VERSION ""

NS_ :

BS_:

BU_: XXX

BO_ 85 CID_QSLGZN: 8 XXX
 SG_ sig_kaaimy : 40|1@1+ (1,0) [0|1] "" XXX
 SG_ sig_qomzev : 56|8@1+ (1,0) [0|255] "" XXX

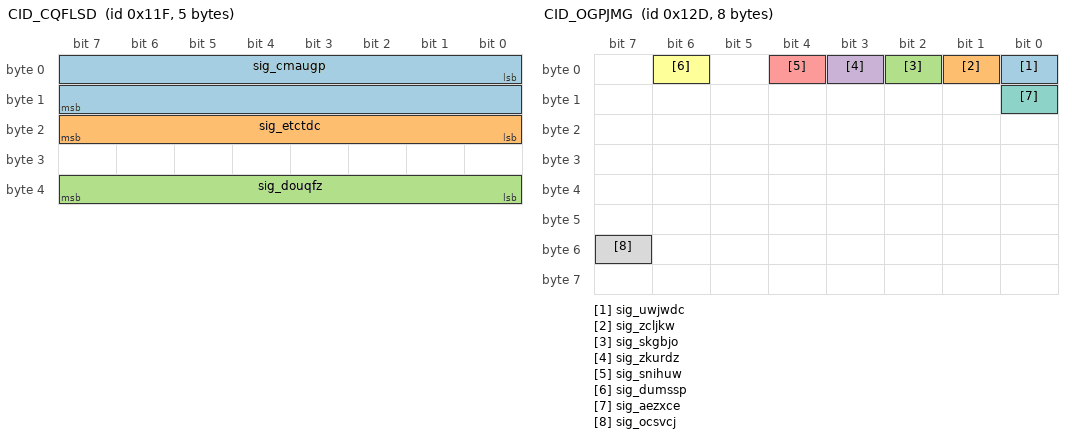
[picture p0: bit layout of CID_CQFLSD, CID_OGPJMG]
BO_ 287 CID_CQFLSD: 5 XXX
 SG_ sig_cmaugp : 0|16@1- (0.1,0) [-450|450] "" XXX
 SG_ sig_etctdc : 16|8@1+ (4,0) [0|1020] "" XXX
 SG_ sig_douqfz : 32|8@1+ (1,0) [0|255] "" XXX

BO_ 289 CID_GMYCTV: 8 XXX
 SG_ sig_hkwdos : 0|12@1+ (1,0) [0|255] "" XXX

BO_ 301 CID_OGPJMG: 8 XXX
 SG_ sig_uwjwdc : 0|1@0+ (1,0) [0|1] "" XXX
 SG_ sig_zcljkw : 1|1@0+ (1,0) [0|1] "" XXX
 SG_ sig_skgbjo : 2|1@0+ (1,0) [0|1] "" XXX
 SG_ sig_zkurdz : 3|1@0+ (1,0) [0|1] "" XXX
 SG_ sig_snihuw : 4|1@0+ (1,0) [0|1] "" XXX
 SG_ sig_dumssp : 6|1@0+ (1,0) [0|1] "" XXX
 SG_ sig_aezxce : 8|1@0+ (1,0) [0|1] "" XXX
 SG_ sig_ocsvcj : 55|1@0+ (1,0) [0|1] "" XXX

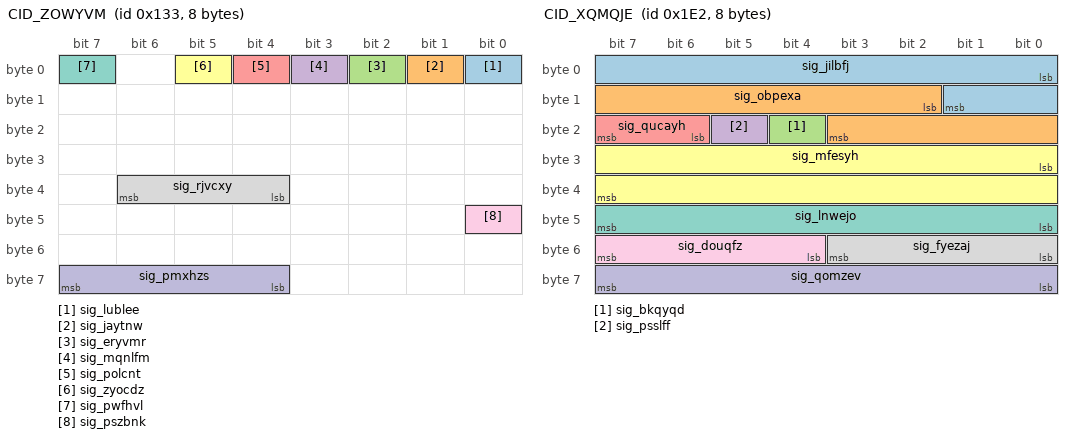
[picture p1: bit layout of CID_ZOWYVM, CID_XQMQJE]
BO_ 307 CID_ZOWYVM: 8 XXX
 SG_ sig_lublee : 0|1@0+ (1,0) [0|1] "" XXX
 SG_ sig_jaytnw : 1|1@1+ (1,0) [0|1] "" XXX
 SG_ sig_eryvmr : 2|1@1+ (1,0) [0|1] "" XXX
 SG_ sig_mqnlfm : 3|1@1+ (1,0) [0|1] "" XXX
 SG_ sig_polcnt : 4|1@0+ (1,0) [0|1] "" XXX
 SG_ sig_zyocdz : 5|1@0+ (1,0) [0|1] "" XXX
 SG_ sig_pwfhvl : 7|1@0+ (1,0) [0|1] "" XXX
 SG_ sig_rjvcxy : 36|3@1+ (1,0) [0|7] "" XXX
 SG_ sig_pszbnk : 40|1@0+ (1,0) [0|1] "" XXX
 SG_ sig_pmxhzs : 63|4@0+ (1,0) [0|15] "" XXX

BO_ 482 CID_XQMQJE: 8 XXX
 SG_ sig_jilbfj : 0|10@1- (0.01,0) [0|5] "" XXX
 SG_ sig_obpexa : 10|10@1- (0.01,0) [-5|0] "" XXX
 SG_ sig_bkqyqd : 20|1@0+ (1,0) [0|1] "" XXX
 SG_ sig_psslff : 21|1@0+ (1,0) [0|1] "" XXX
 SG_ sig_qucayh : 22|2@1+ (1,0) [0|1] "" XXX
 SG_ sig_mfesyh : 24|16@1- (0.1,0) [-780|779.9] "" XXX
 SG_ sig_lnwejo : 47|8@0+ (1,0) [0|255] "" XXX
 SG_ sig_fyezaj : 48|4@1+ (1,0) [0|15] "" XXX
 SG_ sig_douqfz : 52|4@1+ (1,0) [0|15] "" XXX
 SG_ sig_qomzev : 56|8@1+ (1,0) [0|255] "" XXX

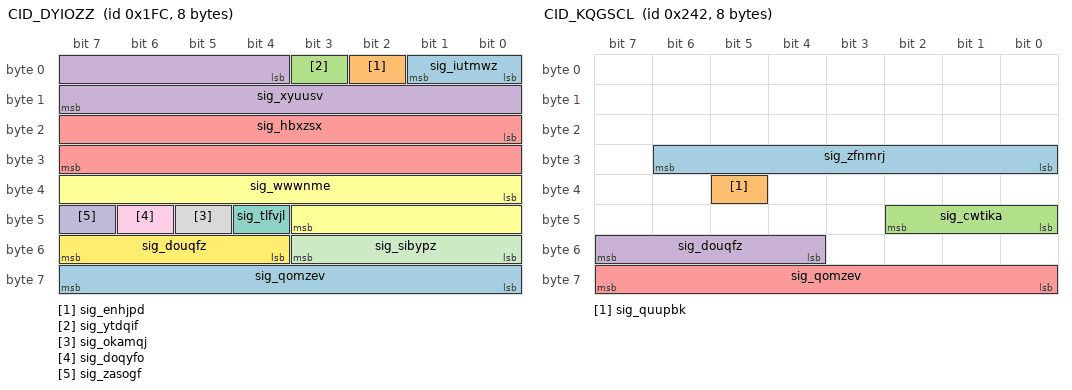
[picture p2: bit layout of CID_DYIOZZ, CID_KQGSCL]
BO_ 508 CID_DYIOZZ: 8 XXX
 SG_ sig_iutmwz : 0|2@1+ (1,0) [0|1] "" XXX
 SG_ sig_enhjpd : 2|1@1+ (1,0) [0|1] "" XXX
 SG_ sig_ytdqif : 3|1@0+ (1,0) [0|1] "" XXX
 SG_ sig_xyuusv : 4|12@1- (1,0) [-2048|2047] "" XXX
 SG_ sig_hbxzsx : 16|16@1- (0.1,0) [-780|779.9] "Deg" XXX
 SG_ sig_wwwnme : 32|12@1- (0.01,0) [0|63] "" XXX
 SG_ sig_tlfvjl : 44|1@0+ (1,0) [0|1] "" XXX
 SG_ sig_okamqj : 45|1@1+ (1,0) [0|255] "" XXX
 SG_ sig_doqyfo : 46|1@1+ (1,0) [0|1] "" XXX
 SG_ sig_zasogf : 47|1@0+ (1,0) [0|3] "" XXX
 SG_ sig_sibypz : 48|4@1+ (1,0) [0|15] "" XXX
 SG_ sig_douqfz : 52|4@1+ (1,0) [0|15] "" XXX
 SG_ sig_qomzev : 56|8@1+ (1,0) [0|255] "" XXX

BO_ 578 CID_KQGSCL: 8 XXX
 SG_ sig_zfnmrj : 30|7@0+ (1,0) [0|127] "" XXX
 SG_ sig_quupbk : 37|1@0+ (1,0) [0|1] "" XXX
 SG_ sig_cwtika : 40|3@1+ (1,0) [0|7] "" XXX
 SG_ sig_douqfz : 55|4@0+ (1,0) [0|15] "" XXX
 SG_ sig_qomzev : 56|8@1+ (1,0) [0|255] "" XXX

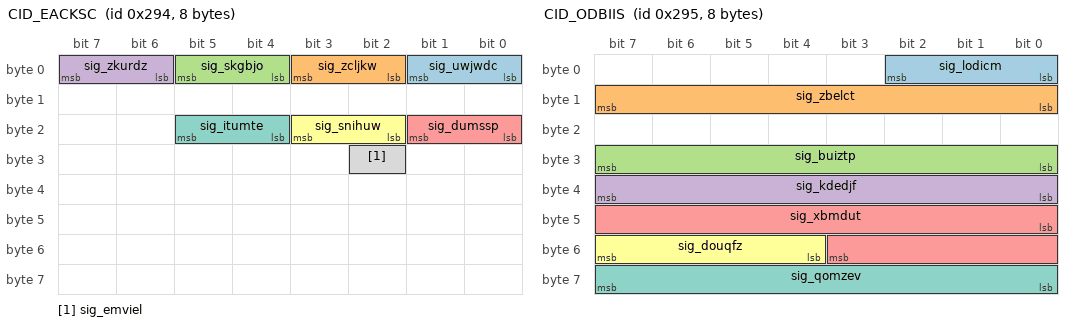
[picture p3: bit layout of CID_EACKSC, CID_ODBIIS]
BO_ 660 CID_EACKSC: 8 XXX
 SG_ sig_uwjwdc : 1|2@0+ (1,0) [0|3] "" XXX
 SG_ sig_zcljkw : 3|2@0+ (1,0) [0|3] "" XXX
 SG_ sig_skgbjo : 5|2@0+ (1,0) [0|3] "" XXX
 SG_ sig_zkurdz : 7|2@0+ (1,0) [0|3] "" XXX
 SG_ sig_dumssp : 17|2@0+ (1,0) [0|3] "" XXX
 SG_ sig_snihuw : 19|2@0+ (1,0) [0|3] "" XXX
 SG_ sig_itumte : 21|2@0+ (1,0) [0|3] "" XXX
 SG_ sig_emviel : 26|1@0+ (1,0) [0|1] "" XXX

BO_ 661 CID_ODBIIS: 8 XXX
 SG_ sig_lodicm : 2|3@0+ (1,0) [0|7] "" XXX
 SG_ sig_zbelct : 15|8@0+ (1,0) [0|255] "" XXX
 SG_ sig_buiztp : 31|8@0+ (1,0) [0|255] "" XXX
 SG_ sig_kdedjf : 32|8@1+ (1,0) [0|255] "" XXX
 SG_ sig_xbmdut : 40|12@1+ (1,0) [0|255] "" XXX
 SG_ sig_douqfz : 52|4@1+ (1,0) [0|15] "" XXX
 SG_ sig_qomzev : 63|8@0+ (1,0) [0|255] "" XXX

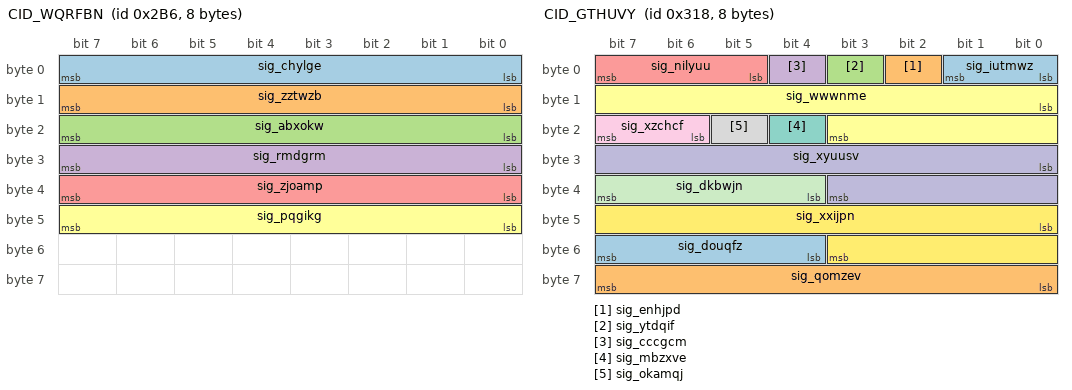
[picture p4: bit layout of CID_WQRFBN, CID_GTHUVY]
BO_ 694 CID_WQRFBN: 8 XXX
 SG_ sig_chylge : 7|8@0+ (1,0) [0|255] "" XXX
 SG_ sig_zztwzb : 15|8@0+ (1,0) [0|255] "" XXX
 SG_ sig_abxokw : 23|8@0+ (1,0) [0|255] "" XXX
 SG_ sig_rmdgrm : 31|8@0+ (1,0) [0|255] "" XXX
 SG_ sig_zjoamp : 39|8@0+ (1,0) [0|255] "" XXX
 SG_ sig_pqgikg : 47|8@0+ (1,0) [0|255] "" XXX

BO_ 790 CID_XFBVQJ: 8 XXX
 SG_ sig_ikzxrb : 3|4@0+ (1,0) [0|1] "" XXX
 SG_ sig_jbtudz : 4|2@1+ (1,0) [0|3] "" XXX
 SG_ sig_bneoxs : 6|2@1+ (1,0) [0|3] "" XXX
 SG_ sig_vgivbn : 8|2@1+ (1,0) [0|3] "" XXX
 SG_ sig_bjxtpp : 10|1@1+ (1,0) [0|1] "" XXX
 SG_ sig_oitzdg : 11|4@1+ (1,0) [0|1] "" XXX
 SG_ sig_bchklg : 15|1@0+ (1,0) [0|1] "" XXX
 SG_ sig_mfesyh : 16|11@1- (1,0) [-1024|1023] "" XXX
 SG_ sig_bkqyqd : 27|1@1+ (1,0) [0|1] "" XXX
 SG_ sig_psslff : 28|1@1+ (1,0) [0|3] "" XXX
 SG_ sig_rpmbgt : 29|1@0+ (1,0) [0|1] "" XXX
 SG_ sig_ahbkpp : 30|1@0+ (1,0) [0|1] "" XXX
 SG_ sig_ujplgt : 31|1@0+ (1,0) [0|1] "" XXX
 SG_ sig_lvrget : 32|2@1+ (1,0) [0|3] "" XXX
 SG_ sig_insdek : 34|2@1+ (1,0) [0|3] "" XXX
 SG_ sig_gfedbs : 36|4@1+ (1,0) [0|3] "" XXX
 SG_ sig_juyndg : 40|8@1+ (5,-5) [-5|1270] "" XXX
 SG_ sig_tcztfe : 49|2@0+ (1,0) [0|3] "" XXX
 SG_ sig_uvfhti : 51|2@0+ (1,0) [0|3] "" XXX
 SG_ sig_douqfz : 52|4@1+ (1,0) [0|15] "" XXX
 SG_ sig_qomzev : 56|8@1+ (1,0) [0|15] "" XXX

BO_ 792 CID_GTHUVY: 8 XXX
 SG_ sig_iutmwz : 0|2@1+ (1,0) [0|1] "" XXX
 SG_ sig_enhjpd : 2|1@1+ (1,0) [0|1] "" XXX
 SG_ sig_ytdqif : 3|1@1+ (1,0) [0|1] "" XXX
 SG_ sig_cccgcm : 4|1@1+ (1,0) [0|1] "" XXX
 SG_ sig_nilyuu : 5|3@1+ (1,0) [0|1] "" XXX
 SG_ sig_wwwnme : 8|12@1- (1,0) [-2048|2047] "" XXX
 SG_ sig_mbzxve : 20|1@1+ (1,0) [0|1] "" XXX
 SG_ sig_okamqj : 21|1@1+ (1,0) [0|1] "" XXX
 SG_ sig_xzchcf : 22|2@1+ (1,0) [0|15] "" XXX
 SG_ sig_xyuusv : 24|12@1- (1,0) [-2048|2047] "" XXX
 SG_ sig_dkbwjn : 36|4@1+ (1,0) [0|15] "" XXX
 SG_ sig_xxijpn : 40|12@1+ (1,0) [0|4095] "" XXX
 SG_ sig_douqfz : 52|4@1+ (1,0) [0|15] "" XXX
 SG_ sig_qomzev : 56|8@1+ (1,0) [0|255] "" XXX

BO_ 813 CID_NGPYLM: 8 XXX
 SG_ sig_xguccc : 0|9@1+ (0.5,0) [0|255.5] "" XXX
 SG_ sig_zjuxgf : 9|1@1+ (1,0) [0|1] "" XXX
 SG_ sig_ienwac : 10|3@1+ (1,0) [0|7] "" XXX
 SG_ sig_emctvm : 13|3@1+ (1,0) [0|7] "" XXX
 SG_ sig_gbkifq : 16|1@1+ (1,0) [0|1] "" XXX
 SG_ sig_mnkjgo : 17|1@1+ (1,0) [0|1] "" XXX
 SG_ sig_ytdqif : 18|1@1+ (1,0) [0|1] "" XXX
 SG_ sig_pnemyu : 19|3@1+ (1,0) [0|1] "" XXX
 SG_ sig_vvgvya : 22|1@0+ (1,0) [0|1] "" XXX
 SG_ sig_wpscbp : 23|1@0+ (1,0) [0|1] "" XXX
 SG_ sig_vgivbn : 24|1@1+ (1,0) [0|1] "" XXX
 SG_ sig_sllsbl : 25|7@1+ (1,0) [0|127] "" XXX
 SG_ sig_quqnip : 32|4@1+ (1,0) [0|15] "" XXX
 SG_ sig_dyvfen : 36|12@1+ (1,0) [0|4095] "" XXX
 SG_ sig_douqfz : 48|4@1+ (1,0) [0|15] "" XXX
 SG_ sig_sfdsag : 55|4@0+ (1,0) [0|15] "" XXX
 SG_ sig_qomzev : 56|8@1+ (1,0) [0|255] "" XXX

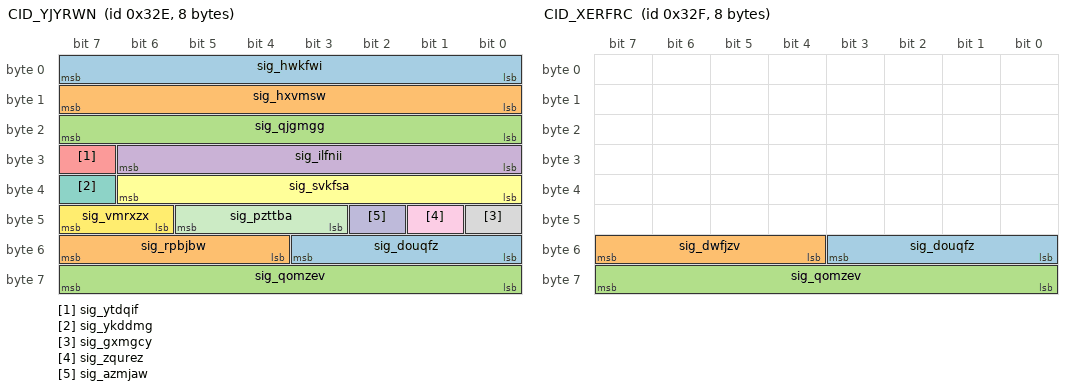
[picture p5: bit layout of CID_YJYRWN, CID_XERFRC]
BO_ 814 CID_YJYRWN: 8 XXX
 SG_ sig_hwkfwi : 0|8@1+ (0.05,-5) [-100|155] "" XXX
 SG_ sig_hxvmsw : 8|8@1+ (0.05,-5) [0|1.26] "" XXX
 SG_ sig_qjgmgg : 16|8@1+ (0.05,-5) [0|1.26] "" XXX
 SG_ sig_ilfnii : 24|7@1+ (0.2,0) [0|12.7] "" XXX
 SG_ sig_ytdqif : 31|1@0+ (1,0) [0|1] "" XXX
 SG_ sig_svkfsa : 32|7@1+ (0.2,-16) [0|12.7] "" XXX
 SG_ sig_ykddmg : 39|1@0+ (1,0) [0|1] "" XXX
 SG_ sig_gxmgcy : 40|1@0+ (1,0) [0|1] "" XXX
 SG_ sig_zqurez : 41|1@0+ (1,0) [0|1] "" XXX
 SG_ sig_azmjaw : 42|1@1+ (1,0) [0|3] "" XXX
 SG_ sig_pzttba : 45|3@0+ (1,0) [0|1] "" XXX
 SG_ sig_vmrxzx : 46|2@1+ (1,0) [0|3] "" XXX
 SG_ sig_douqfz : 48|4@1+ (1,0) [0|15] "" XXX
 SG_ sig_rpbjbw : 55|4@0+ (1,0) [0|15] "" XXX
 SG_ sig_qomzev : 56|8@1+ (1,0) [0|255] "" XXX

BO_ 815 CID_XERFRC: 8 XXX
 SG_ sig_douqfz : 48|4@1+ (1,0) [0|15] "" XXX
 SG_ sig_dwfjzv : 55|4@0+ (1,0) [0|15] "" XXX
 SG_ sig_qomzev : 56|8@1+ (1,0) [0|255] "" XXX

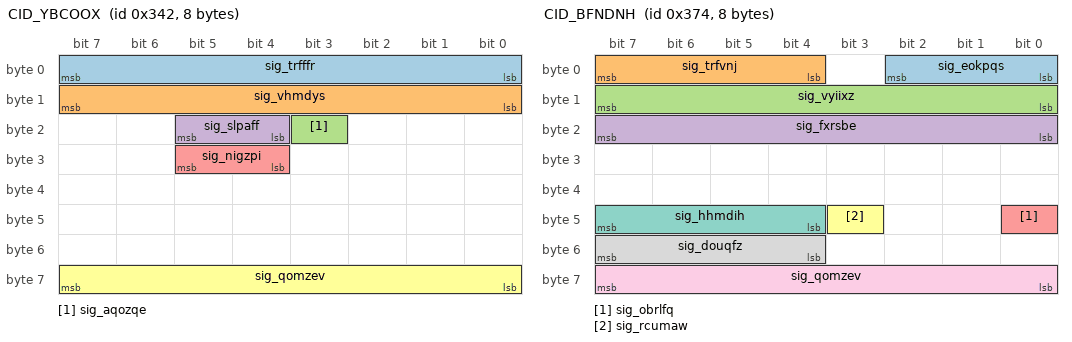
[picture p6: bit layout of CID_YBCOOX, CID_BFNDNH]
BO_ 834 CID_YBCOOX: 8 XXX
 SG_ sig_trfffr : 0|8@1+ (0.01,0) [0|2.55] "" XXX
 SG_ sig_vhmdys : 8|8@1+ (0.01,0) [0|2.55] "" XXX
 SG_ sig_aqozqe : 19|1@1+ (1,0) [0|1] "" XXX
 SG_ sig_slpaff : 20|2@1+ (1,0) [0|255] "" XXX
 SG_ sig_nigzpi : 28|2@1+ (1,0) [0|1] "" XXX
 SG_ sig_qomzev : 56|8@1+ (1,0) [0|255] "" XXX

 BO_ 884 CID_BFNDNH: 8 MRR
 SG_ sig_eokpqs : 2|3@0+ (1,0) [0|3] "" MRR
 SG_ sig_trfvnj : 7|4@0+ (1,0) [0|15] "" MRR
 SG_ sig_vyiixz : 15|8@0+ (0.1,-12) [0|255] "" MRR
 SG_ sig_fxrsbe : 23|8@0+ (1,-100) [0|255] "" MRR
 SG_ sig_obrlfq : 40|1@0+ (1,0) [0|3] "" MRR
 SG_ sig_rcumaw : 43|1@0+ (1,0) [0|1] "" XXX
 SG_ sig_hhmdih : 44|4@1+ (1,0) [0|15] "" XXX
 SG_ sig_douqfz : 52|4@1+ (1,0) [0|15] "" MRR
 SG_ sig_qomzev : 56|8@1+ (1,0) [0|255] "" MRR

BO_ 944 CID_ZJJZNE: 8 XXX
 SG_ sig_othvds : 1|2@0+ (1,0) [0|3] "" XXX
 SG_ sig_mmpery : 2|1@0+ (1,0) [0|1] "" XXX
 SG_ sig_cdkihw : 4|2@0+ (1,0) [0|3] "" XXX
 SG_ sig_rqtctv : 5|1@0+ (1,0) [0|1] "" XXX
 SG_ sig_vylajm : 6|1@0+ (1,0) [0|1] "" XXX
 SG_ sig_tpydsr : 7|1@0+ (1,0) [0|1] "" XXX
 SG_ sig_mnmkuo : 8|1@0+ (1,0) [0|1] "" XXX
 SG_ sig_hqlzon : 11|3@0+ (1,0) [0|7] "" XXX
 SG_ sig_ybkqsp : 12|1@0+ (1,0) [0|1] "" XXX
 SG_ sig_kmwymf : 14|2@0+ (1,0) [0|3] "" XXX
 SG_ sig_gsvszp : 15|1@0+ (1,0) [0|1] "" XXX
 SG_ sig_wxduqq : 16|1@0+ (1,0) [0|1] "" XXX
 SG_ sig_xzyhis : 18|2@0+ (1,0) [0|3] "" XXX
 SG_ sig_hgmxtb : 19|1@0+ (1,0) [0|1] "" XXX
 SG_ sig_gjctkz : 23|4@0+ (1,0) [0|15] "" XXX
 SG_ sig_jkflrx : 24|28@1+ (1,0) [0|268435455] "" XXX
 SG_ sig_douqfz : 52|4@1+ (1,0) [0|15] "" XXX
 SG_ sig_qomzev : 56|8@1+ (1,0) [0|255] "" XXX

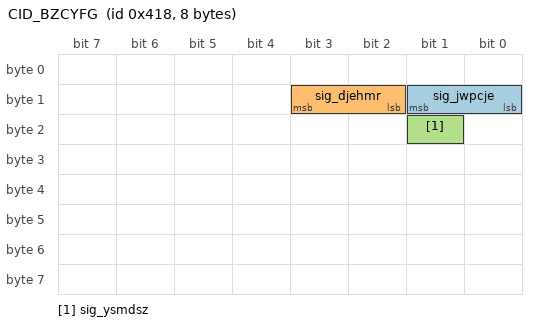
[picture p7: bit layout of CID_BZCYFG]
BO_ 1048 CID_BZCYFG: 8 XXX
 SG_ sig_jwpcje : 9|2@0+ (1,0) [0|1] "" XXX
 SG_ sig_djehmr : 11|2@0+ (1,0) [0|1] "" XXX
 SG_ sig_ysmdsz : 17|1@0+ (1,0) [0|1] "" XXX

VAL_ 578 sig_cwtika 4 "D" 2 "R" 3 "N" 1 "P";
VAL_ 790 sig_ikzxrb 11 "AutoFullBeamActive" 2 "AutoFullBeamInactive";
VAL_ 790 sig_jbtudz 0 "GRAY" 1 "GREEN" 2 "YELLOW" 3 "RED";
VAL_ 790 sig_bneoxs 3 "ALARM_AND_LKA" 2 "LKA" 1 "ALARM" 0 "DISABLE";
VAL_ 790 sig_insdek 0 "GRAY" 1 "GREEN" 2 "YELLOW" 3 "RED";
VAL_ 790 sig_tcztfe 0 "VIBRATION" 1 "AUDIO" 2 "AUDIO_AND_VIBRATION";
VAL_ 792 sig_iutmwz 0 "NotReady" 1 "Ready" 2 "Active" 3 "TemporaryFail";
VAL_ 813 sig_ienwac 4 "4BAR" 3 "3BAR" 2 "2BAR" 1 "1BAR";
VAL_ 813 sig_pnemyu 0 "OFF" 2 "ACC_ON" 3 "ACC_ACTIVE" 5 "FORCE_ACCEL" 7 "ERROR";
VAL_ 813 sig_sllsbl 36 "ACC_ERROR" 22 "OVERRIDE" 12 "ENGAGE" 8 "DISENGAGE" 20 "ACC_ON" 32 "ACC_OFF" 48 "CHECK_GEAR_D" 16 "FORCE_ACCEL" 0 "NONE";
VAL_ 814 sig_pzttba 0 "Off" 1 "Passive" 2 "StandBy" 3 "ActiveControl" 4 "BrakeOnly" 5 "Override" 6 "Standstill" 7 "Failure";
VAL_ 814 sig_vmrxzx 0 "Softoff" 1 "Fastoff" 2 "Immediateoff" 3 "Initial";
VAL_ 834 sig_slpaff 2 "SPORT" 1 "ECO" 0 "SNOW";
VAL_ 834 sig_nigzpi 3 "HEV" 2 "FORCE_EV" 1 "EV";
VAL_ 944 sig_cdkihw 0 "NOTPRESSED" 1 "DOWN_SETSPEED" 3 "UP_RESETSPEED";
